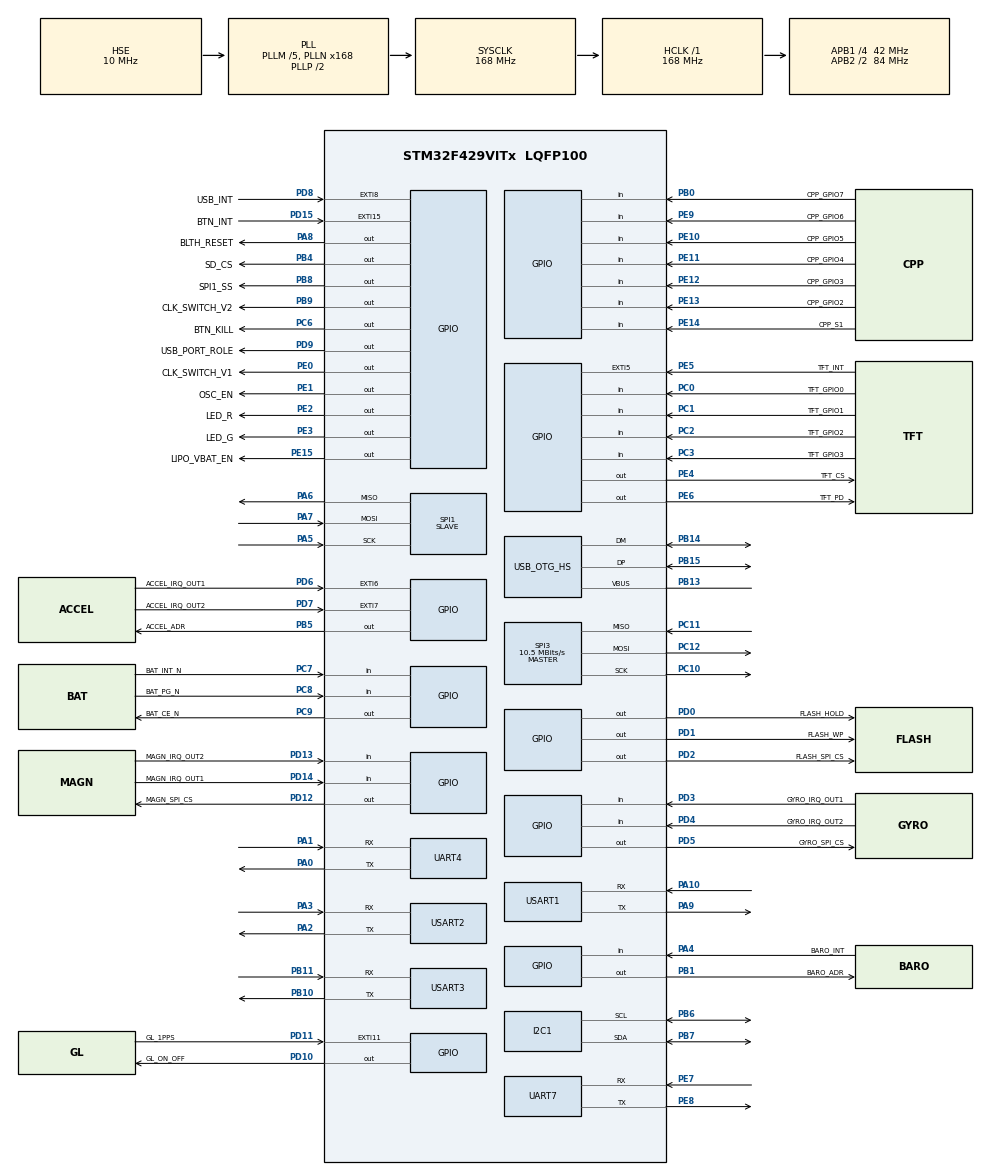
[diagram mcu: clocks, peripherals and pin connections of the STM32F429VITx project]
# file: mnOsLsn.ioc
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Dma.Request0=SPI3_TX
Dma.Request1=SPI3_RX
Dma.Request2=UART4_RX
Dma.Request3=USART2_RX
Dma.Request4=UART4_TX
Dma.Request5=USART2_TX
Dma.Request6=USART3_RX
Dma.Request7=UART7_RX
Dma.Request8=USART1_RX
Dma.SPI3_RX.1.Direction=DMA_PERIPH_TO_MEMORY
Dma.SPI3_RX.1.FIFOMode=DMA_FIFOMODE_DISABLE
Dma.SPI3_RX.1.Instance=DMA1_Stream0
Dma.SPI3_RX.1.MemDataAlignment=DMA_MDATAALIGN_BYTE
Dma.SPI3_RX.1.MemInc=DMA_MINC_ENABLE
Dma.SPI3_RX.1.Mode=DMA_NORMAL
Dma.SPI3_RX.1.PeriphDataAlignment=DMA_PDATAALIGN_BYTE
Dma.SPI3_RX.1.PeriphInc=DMA_PINC_DISABLE
Dma.SPI3_RX.1.Priority=DMA_PRIORITY_MEDIUM
Dma.SPI3_TX.0.Direction=DMA_MEMORY_TO_PERIPH
Dma.SPI3_TX.0.FIFOMode=DMA_FIFOMODE_DISABLE
Dma.SPI3_TX.0.Instance=DMA1_Stream7
Dma.SPI3_TX.0.MemDataAlignment=DMA_MDATAALIGN_BYTE
Dma.SPI3_TX.0.MemInc=DMA_MINC_ENABLE
Dma.SPI3_TX.0.Mode=DMA_NORMAL
Dma.SPI3_TX.0.PeriphDataAlignment=DMA_PDATAALIGN_BYTE
Dma.SPI3_TX.0.PeriphInc=DMA_PINC_DISABLE
Dma.SPI3_TX.0.Priority=DMA_PRIORITY_MEDIUM
Dma.UART4_RX.2.Direction=DMA_PERIPH_TO_MEMORY
Dma.UART4_RX.2.FIFOMode=DMA_FIFOMODE_DISABLE
Dma.UART4_RX.2.Instance=DMA1_Stream2
Dma.UART4_RX.2.MemDataAlignment=DMA_MDATAALIGN_BYTE
Dma.UART4_RX.2.MemInc=DMA_MINC_ENABLE
Dma.UART4_RX.2.Mode=DMA_CIRCULAR
Dma.UART4_RX.2.PeriphDataAlignment=DMA_PDATAALIGN_BYTE
Dma.UART4_RX.2.PeriphInc=DMA_PINC_DISABLE
Dma.UART4_RX.2.Priority=DMA_PRIORITY_HIGH
Dma.UART4_TX.4.Direction=DMA_MEMORY_TO_PERIPH
Dma.UART4_TX.4.FIFOMode=DMA_FIFOMODE_DISABLE
Dma.UART4_TX.4.Instance=DMA1_Stream4
Dma.UART4_TX.4.MemDataAlignment=DMA_MDATAALIGN_BYTE
Dma.UART4_TX.4.MemInc=DMA_MINC_ENABLE
Dma.UART4_TX.4.Mode=DMA_NORMAL
Dma.UART4_TX.4.PeriphDataAlignment=DMA_PDATAALIGN_BYTE
Dma.UART4_TX.4.PeriphInc=DMA_PINC_DISABLE
Dma.UART4_TX.4.Priority=DMA_PRIORITY_LOW
Dma.UART7_RX.7.Direction=DMA_PERIPH_TO_MEMORY
Dma.UART7_RX.7.FIFOMode=DMA_FIFOMODE_DISABLE
Dma.UART7_RX.7.Instance=DMA1_Stream3
Dma.UART7_RX.7.MemDataAlignment=DMA_MDATAALIGN_BYTE
Dma.UART7_RX.7.MemInc=DMA_MINC_ENABLE
Dma.UART7_RX.7.Mode=DMA_CIRCULAR
Dma.UART7_RX.7.PeriphDataAlignment=DMA_PDATAALIGN_BYTE
Dma.UART7_RX.7.PeriphInc=DMA_PINC_DISABLE
Dma.UART7_RX.7.Priority=DMA_PRIORITY_HIGH
Dma.USART1_RX.8.Direction=DMA_PERIPH_TO_MEMORY
Dma.USART1_RX.8.FIFOMode=DMA_FIFOMODE_DISABLE
Dma.USART1_RX.8.Instance=DMA2_Stream2
Dma.USART1_RX.8.MemDataAlignment=DMA_MDATAALIGN_BYTE
Dma.USART1_RX.8.MemInc=DMA_MINC_ENABLE
Dma.USART1_RX.8.Mode=DMA_CIRCULAR
Dma.USART1_RX.8.PeriphDataAlignment=DMA_PDATAALIGN_BYTE
Dma.USART1_RX.8.PeriphInc=DMA_PINC_DISABLE
Dma.USART1_RX.8.Priority=DMA_PRIORITY_MEDIUM
Dma.USART2_RX.3.Direction=DMA_PERIPH_TO_MEMORY
Dma.USART2_RX.3.FIFOMode=DMA_FIFOMODE_DISABLE
Dma.USART2_RX.3.Instance=DMA1_Stream5
Dma.USART2_RX.3.MemDataAlignment=DMA_MDATAALIGN_BYTE
Dma.USART2_RX.3.MemInc=DMA_MINC_ENABLE
Dma.USART2_RX.3.Mode=DMA_CIRCULAR
Dma.USART2_RX.3.PeriphDataAlignment=DMA_PDATAALIGN_BYTE
Dma.USART2_RX.3.PeriphInc=DMA_PINC_DISABLE
Dma.USART2_RX.3.Priority=DMA_PRIORITY_HIGH
Dma.USART2_TX.5.Direction=DMA_MEMORY_TO_PERIPH
Dma.USART2_TX.5.FIFOMode=DMA_FIFOMODE_DISABLE
Dma.USART2_TX.5.Instance=DMA1_Stream6
Dma.USART2_TX.5.MemDataAlignment=DMA_MDATAALIGN_BYTE
Dma.USART2_TX.5.MemInc=DMA_MINC_ENABLE
Dma.USART2_TX.5.Mode=DMA_NORMAL
Dma.USART2_TX.5.PeriphDataAlignment=DMA_PDATAALIGN_BYTE
Dma.USART2_TX.5.PeriphInc=DMA_PINC_DISABLE
Dma.USART2_TX.5.Priority=DMA_PRIORITY_LOW
Dma.USART3_RX.6.Direction=DMA_PERIPH_TO_MEMORY
Dma.USART3_RX.6.FIFOMode=DMA_FIFOMODE_DISABLE
Dma.USART3_RX.6.Instance=DMA1_Stream1
Dma.USART3_RX.6.MemDataAlignment=DMA_MDATAALIGN_BYTE
Dma.USART3_RX.6.MemInc=DMA_MINC_ENABLE
Dma.USART3_RX.6.Mode=DMA_CIRCULAR
Dma.USART3_RX.6.PeriphDataAlignment=DMA_PDATAALIGN_BYTE
Dma.USART3_RX.6.PeriphInc=DMA_PINC_DISABLE
Dma.USART3_RX.6.Priority=DMA_PRIORITY_HIGH
FATFS._FS_LOCK=3
FATFS._USE_LFN=3
FATFS._USE_MUTEX=1
FATFS._USE_STRFUNC=1
FREERTOS.BinarySemaphores01=semSpi,Dynamic,NULL;semInitPpm,Dynamic,NULL;semSyncTime,Dynamic,NULL
FREERTOS.Queues01=qSpi,16,SpiQNode,0,Dynamic,NULL,NULL;qI2c,16,I2cQNode,0,Dynamic,NULL,NULL;qGNSS_Tx1,16,String,0,Dynamic,NULL,NULL;qPPM_Tx0,16,String,0,Dynamic,NULL,NULL;qCDC_Rx,16,CDCRxData,0,Dynamic,NULL,NULL;qCDC_Tx,16,String,0,Dynamic,NULL,NULL;qMI_Tx,16,String,0,Dynamic,NULL,NULL;qJetTx,16,String,0,Dynamic,NULL,NULL;qBlthTx,16,String,0,Dynamic,NULL,NULL
FREERTOS.Tasks01=main,24,224,start_main,Default,NULL,Dynamic,NULL,NULL
FREERTOS.Timers01=tmrSyncTime,callbackTmrSyncTime,osTimerPeriodic,Default,NULL,Dynamic,NULL
FREERTOS.configCHECK_FOR_STACK_OVERFLOW=2
FREERTOS.configGENERATE_RUN_TIME_STATS=1
FREERTOS.configTOTAL_HEAP_SIZE=131072
FREERTOS.configUSE_MALLOC_FAILED_HOOK=1
FREERTOS.configUSE_NEWLIB_REENTRANT=1
FREERTOS.configUSE_POSIX_ERRNO=0
FREERTOS.configUSE_STATS_FORMATTING_FUNCTIONS=1
I2C1.AddressingMode=I2C_ADDRESSINGMODE_7BIT
I2C1.DualAddressMode=I2C_DUALADDRESS_DISABLE
I2C1.GeneralCallMode=I2C_GENERALCALL_DISABLE
I2C1.I2C_Mode=I2C_Fast
I2C1.NoStretchMode=I2C_NOSTRETCH_DISABLE
I2C1.OwnAddress=0
Mcu.Family=STM32F4
Mcu.Name=STM32F429VITx
Mcu.Package=LQFP100
NVIC.DMA1_Stream0_IRQn=true\:5\:0\:false\:false\:true\:true\:false\:true\:true
NVIC.DMA1_Stream1_IRQn=true\:5\:0\:false\:false\:true\:true\:false\:true\:true
NVIC.DMA1_Stream2_IRQn=true\:5\:0\:false\:false\:true\:true\:false\:true\:true
NVIC.DMA1_Stream3_IRQn=true\:5\:0\:false\:false\:true\:true\:false\:true\:true
NVIC.DMA1_Stream4_IRQn=true\:5\:0\:false\:false\:true\:true\:false\:true\:true
NVIC.DMA1_Stream5_IRQn=true\:5\:0\:false\:false\:true\:true\:false\:true\:true
NVIC.DMA1_Stream6_IRQn=true\:5\:0\:false\:false\:true\:true\:false\:true\:true
NVIC.DMA1_Stream7_IRQn=true\:5\:0\:false\:false\:true\:true\:false\:true\:true
NVIC.DMA2_Stream2_IRQn=true\:5\:0\:false\:false\:true\:true\:false\:true\:true
NVIC.EXTI15_10_IRQn=true\:5\:0\:false\:false\:true\:true\:true\:true\:true
NVIC.OTG_HS_IRQn=true\:5\:0\:false\:false\:true\:true\:false\:true\:true
NVIC.PriorityGroup=NVIC_PRIORITYGROUP_4
NVIC.TIM1_UP_TIM10_IRQn=true\:0\:0\:false\:false\:true\:false\:false\:true\:true
NVIC.TimeBase=TIM1_UP_TIM10_IRQn
NVIC.TimeBaseIP=TIM1
PA0/WKUP.Mode=Asynchronous
PA0/WKUP.Signal=UART4_TX
PA1.Mode=Asynchronous
PA1.Signal=UART4_RX
PA10.Mode=Asynchronous
PA10.Signal=USART1_RX
PA11.Signal=USART1_CTS
PA12.Signal=USART1_RTS
PA13.Mode=Serial_Wire
PA13.Signal=SYS_JTMS-SWDIO
PA14.Mode=Serial_Wire
PA14.Signal=SYS_JTCK-SWCLK
PA2.Mode=Asynchronous
PA2.Signal=USART2_TX
PA3.Mode=Asynchronous
PA3.Signal=USART2_RX
PA4.GPIO_Label=BARO_INT
PA4.Signal=GPIO_Input
PA5.Mode=Full_Duplex_Slave
PA5.Signal=SPI1_SCK
PA6.Mode=Full_Duplex_Slave
PA6.Signal=SPI1_MISO
PA7.Mode=Full_Duplex_Slave
PA7.Signal=SPI1_MOSI
PA8.GPIO_Label=BLTH_RESET
PA8.GPIO_Speed=GPIO_SPEED_FREQ_VERY_HIGH
PA8.Signal=GPIO_Output
PA9.Mode=Asynchronous
PA9.Signal=USART1_TX
PB0.GPIO_Label=CPP_GPIO7
PB0.Signal=GPIO_Input
PB1.GPIO_Label=BARO_ADR
PB1.GPIO_Speed=GPIO_SPEED_FREQ_LOW
PB1.Signal=GPIO_Output
PB10.Mode=Asynchronous
PB10.Signal=USART3_TX
PB11.Mode=Asynchronous
PB11.Signal=USART3_RX
PB12.Signal=USB_OTG_HS_ID
PB13.Mode=Activate_VBUS_FS
PB13.Signal=USB_OTG_HS_VBUS
PB14.Mode=Device_Only_FS
PB14.Signal=USB_OTG_HS_DM
PB15.Mode=Device_Only_FS
PB15.Signal=USB_OTG_HS_DP
PB4.GPIO_Label=SD_CS
PB4.GPIO_Speed=GPIO_SPEED_FREQ_VERY_HIGH
PB4.PinState=GPIO_PIN_SET
PB4.Signal=GPIO_Output
PB5.GPIO_Label=ACCEL_ADR
PB5.Signal=GPIO_Output
PB6.GPIO_Pu=GPIO_PULLUP
PB6.Mode=I2C
PB6.Signal=I2C1_SCL
PB7.GPIO_Pu=GPIO_PULLUP
PB7.Mode=I2C
PB7.Signal=I2C1_SDA
PB8.GPIO_Label=SPI1_SS
PB8.GPIO_Speed=GPIO_SPEED_FREQ_VERY_HIGH
PB8.PinState=GPIO_PIN_SET
PB8.Signal=GPIO_Output
PB9.GPIO_Label=CLK_SWITCH_V2
PB9.GPIO_Speed=GPIO_SPEED_FREQ_VERY_HIGH
PB9.Signal=GPIO_Output
PC0.GPIO_Label=TFT_GPIO0
PC0.Signal=GPIO_Input
PC1.GPIO_Label=TFT_GPIO1
PC1.Signal=GPIO_Input
PC10.Mode=Full_Duplex_Master
PC10.Signal=SPI3_SCK
PC11.Mode=Full_Duplex_Master
PC11.Signal=SPI3_MISO
PC12.Mode=Full_Duplex_Master
PC12.Signal=SPI3_MOSI
PC2.GPIO_Label=TFT_GPIO2
PC2.Signal=GPIO_Input
PC3.GPIO_Label=TFT_GPIO3
PC3.Signal=GPIO_Input
PC6.GPIO_Label=BTN_KILL
PC6.GPIO_Speed=GPIO_SPEED_FREQ_VERY_HIGH
PC6.PinState=GPIO_PIN_SET
PC6.Signal=GPIO_Output
PC7.GPIO_Label=BAT_INT_N
PC7.Signal=GPIO_Input
PC8.GPIO_Label=BAT_PG_N
PC8.Signal=GPIO_Input
PC9.GPIO_Label=BAT_CE_N
PC9.GPIO_Speed=GPIO_SPEED_FREQ_VERY_HIGH
PC9.PinState=GPIO_PIN_RESET
PC9.Signal=GPIO_Output
PD0.GPIO_Label=FLASH_HOLD
PD0.GPIO_Speed=GPIO_SPEED_FREQ_VERY_HIGH
PD0.Signal=GPIO_Output
PD1.GPIO_Label=FLASH_WP
PD1.GPIO_Speed=GPIO_SPEED_FREQ_VERY_HIGH
PD1.Signal=GPIO_Output
PD10.GPIO_Label=GL_ON_OFF
PD10.GPIO_Speed=GPIO_SPEED_FREQ_VERY_HIGH
PD10.Signal=GPIO_Output
PD11.GPIO_Label=GL_1PPS
PD11.Signal=GPXTI11
PD12.GPIO_Label=MAGN_SPI_CS
PD12.GPIO_Speed=GPIO_SPEED_FREQ_VERY_HIGH
PD12.PinState=GPIO_PIN_SET
PD12.Signal=GPIO_Output
PD13.GPIO_Label=MAGN_IRQ_OUT2
PD13.Signal=GPIO_Input
PD14.GPIO_Label=MAGN_IRQ_OUT1
PD14.Signal=GPIO_Input
PD15.GPIO_Label=BTN_INT
PD15.GPIO_ModeDefaultEXTI=GPIO_MODE_IT_FALLING
PD15.Signal=GPXTI15
PD2.GPIO_Label=FLASH_SPI_CS
PD2.GPIO_Speed=GPIO_SPEED_FREQ_VERY_HIGH
PD2.PinState=GPIO_PIN_SET
PD2.Signal=GPIO_Output
PD3.GPIO_Label=GYRO_IRQ_OUT1
PD3.Signal=GPIO_Input
PD4.GPIO_Label=GYRO_IRQ_OUT2
PD4.Signal=GPIO_Input
PD5.GPIO_Label=GYRO_SPI_CS
PD5.GPIO_Speed=GPIO_SPEED_FREQ_VERY_HIGH
PD5.PinState=GPIO_PIN_SET
PD5.Signal=GPIO_Output
PD6.GPIO_Label=ACCEL_IRQ_OUT1
PD6.GPIO_ModeDefaultEXTI=GPIO_MODE_IT_FALLING
PD6.Signal=GPXTI6
PD7.GPIO_Label=ACCEL_IRQ_OUT2
PD7.GPIO_ModeDefaultEXTI=GPIO_MODE_IT_FALLING
PD7.Signal=GPXTI7
PD8.GPIO_Label=USB_INT
PD8.GPIO_ModeDefaultEXTI=GPIO_MODE_IT_FALLING
PD8.GPIO_PuPd=GPIO_PULLUP
PD8.Signal=GPXTI8
PD9.GPIO_Label=USB_PORT_ROLE
PD9.GPIO_Speed=GPIO_SPEED_FREQ_VERY_HIGH
PD9.Signal=GPIO_Output
PE0.GPIO_Label=CLK_SWITCH_V1
PE0.GPIO_Speed=GPIO_SPEED_FREQ_VERY_HIGH
PE0.Signal=GPIO_Output
PE1.GPIO_Label=OSC_EN
PE1.GPIO_Speed=GPIO_SPEED_FREQ_VERY_HIGH
PE1.Signal=GPIO_Output
PE10.GPIO_Label=CPP_GPIO5
PE10.Signal=GPIO_Input
PE11.GPIO_Label=CPP_GPIO4
PE11.Signal=GPIO_Input
PE12.GPIO_Label=CPP_GPIO3
PE12.Signal=GPIO_Input
PE13.GPIO_Label=CPP_GPIO2
PE13.Signal=GPIO_Input
PE14.GPIO_Label=CPP_S1
PE14.Signal=GPIO_Input
PE15.GPIO_Label=LIPO_VBAT_EN
PE15.GPIO_Speed=GPIO_SPEED_FREQ_VERY_HIGH
PE15.Signal=GPIO_Output
PE2.GPIO_Label=LED_R
PE2.Signal=GPIO_Output
PE3.GPIO_Label=LED_G
PE3.Signal=GPIO_Output
PE4.GPIO_Label=TFT_CS
PE4.GPIO_Speed=GPIO_SPEED_FREQ_VERY_HIGH
PE4.PinState=GPIO_PIN_SET
PE4.Signal=GPIO_Output
PE5.GPIO_Label=TFT_INT
PE5.GPIO_ModeDefaultEXTI=GPIO_MODE_IT_FALLING
PE5.Signal=GPXTI5
PE6.GPIO_Label=TFT_PD
PE6.GPIO_Speed=GPIO_SPEED_FREQ_VERY_HIGH
PE6.PinState=GPIO_PIN_RESET
PE6.Signal=GPIO_Output
PE7.Mode=Asynchronous
PE7.Signal=UART7_RX
PE8.Mode=Asynchronous
PE8.Signal=UART7_TX
PE9.GPIO_Label=CPP_GPIO6
PE9.Signal=GPIO_Input
PH0/OSC_IN.Mode=HSE-External-Clock-Source
PH0/OSC_IN.Signal=RCC_OSC_IN
PH1/OSC_OUT.Mode=HSE-External-Clock-Source
PH1/OSC_OUT.Signal=RCC_OSC_OUT
ProjectManager.HeapSize=0x200
ProjectManager.StackSize=0x400
ProjectManager.TargetToolchain=STM32CubeIDE
RCC.48MHZClocksFreq_Value=48000000
RCC.AHBFreq_Value=168000000
RCC.APB1CLKDivider=RCC_HCLK_DIV4
RCC.APB1Freq_Value=42000000
RCC.APB1TimFreq_Value=84000000
RCC.APB2CLKDivider=RCC_HCLK_DIV2
RCC.APB2Freq_Value=84000000
RCC.APB2TimFreq_Value=168000000
RCC.CortexFreq_Value=168000000
RCC.HCLKFreq_Value=168000000
RCC.HSE_VALUE=10000000
RCC.HSI_VALUE=16000000
RCC.LSE_VALUE=32768
RCC.PLLM=5
RCC.PLLN=168
RCC.PLLQ=7
RCC.SYSCLKFreq_VALUE=168000000
RCC.SYSCLKSource=RCC_SYSCLKSOURCE_PLLCLK
RCC.VCOOutputFreq_Value=336000000
RTC.Format=RTC_FORMAT_BIN
RTC.SynchPrediv=249
RTC.WeekDay=RTC_WEEKDAY_FRIDAY
RTC.Year=41
SPI1.Direction=SPI_DIRECTION_2LINES
SPI1.Mode=SPI_MODE_SLAVE
SPI1.VirtualType=VM_SLAVE
SPI3.BaudRatePrescaler=SPI_BAUDRATEPRESCALER_4
SPI3.CalculateBaudRate=10.5 MBits/s
SPI3.Direction=SPI_DIRECTION_2LINES
SPI3.Mode=SPI_MODE_MASTER
SPI3.VirtualType=VM_MASTER
UART4.VirtualMode=Asynchronous
UART7.VirtualMode=Asynchronous
USART1.VirtualMode=VM_ASYNC
USART2.VirtualMode=VM_ASYNC
USART3.VirtualMode=VM_ASYNC
USB_DEVICE.CLASS_NAME_HS=CDC
USB_DEVICE.VirtualMode-CDC_HS=Cdc
USB_DEVICE.VirtualModeHS=Cdc_HS
USB_OTG_HS.VirtualMode-Device_Only_FS=Device_Only_FS
USB_OTG_HS.dma_enable-Device_Only_FS=ENABLE
VP_FATFS_VS_Generic.Mode=User_defined
VP_FREERTOS_VS_CMSIS_V2.Mode=CMSIS_V2
VP_RTC_VS_RTC_Activate.Mode=RTC_Enabled
VP_RTC_VS_RTC_Calendar.Mode=RTC_Calendar
VP_SYS_VS_tim1.Mode=TIM1
VP_USB_DEVICE_VS_USB_DEVICE_CDC_HS.Mode=CDC_HS
board=custom

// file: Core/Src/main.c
/* USER CODE BEGIN Header */
/**
  ******************************************************************************
  * @file           : main.c
  * @brief          : Main program body
  ******************************************************************************
  * @attention
  *
  * <h2><center>&copy; Copyright (c) 2021 STMicroelectronics.
  * All rights reserved.</center></h2>
  *
  * This software component is licensed by ST under BSD 3-Clause license,
  * the "License"; You may not use this file except in compliance with the
  * License. You may obtain a copy of the License at:
  *                        opensource.org/licenses/BSD-3-Clause
  *
  ******************************************************************************
  */
/* USER CODE END Header */
#include "main.h"
#include "cmsis_os.h"
#include "dma.h"
#include "fatfs.h"
#include "i2c.h"
#include "rtc.h"
#include "spi.h"
#include "usart.h"
#include "usb_device.h"
#include "gpio.h"

/* USER CODE BEGIN Includes */
#include "clk_osc.h"
#include "clk_key.h"
#include "system_clk.h"
/* USER CODE END Includes */

void SystemClock_Config(void);
void MX_FREERTOS_Init(void);
/* USER CODE BEGIN PFP */
void SystemClock_ConfigHSI(void);
/* USER CODE END PFP */

int main(void)
{

  /* MCU Configuration--------------------------------------------------------*/

  /* Reset of all peripherals, Initializes the Flash interface and the Systick. */
  HAL_Init();

  /* USER CODE BEGIN Init */
  goto skipSystemClkConfig;
  /* USER CODE END Init */

  /* Configure the system clock */
  SystemClock_Config();

  /* USER CODE BEGIN SysInit */
skipSystemClkConfig:
  SystemClock_ConfigHSI();
  /* USER CODE END SysInit */

  /* Initialize all configured peripherals */
  MX_GPIO_Init();
  MX_DMA_Init();
  MX_I2C1_Init();
  MX_SPI3_Init();
  MX_UART4_Init();
  MX_USART1_UART_Init();
  MX_USART2_UART_Init();
  MX_UART7_Init();
  MX_USART3_UART_Init();
  MX_FATFS_Init();
  MX_RTC_Init();
  MX_SPI1_Init();
  /* USER CODE BEGIN 2 */
  i2c_init();
  clk_osc_config_bp();
  clk_osc_en(oscEnable);
  clk_key_sel_src(clkInternal);
  if (clk_sel_pll_hse()) {
    Error_Handler();
  }
  /* USER CODE END 2 */

  /* Init scheduler */
  osKernelInitialize();  /* Call init function for freertos objects (in freertos.c) */
  MX_FREERTOS_Init();

  /* Start scheduler */
  osKernelStart();

  /* We should never get here as control is now taken by the scheduler */
  /* Infinite loop */
  while (1)
  {

  }
}

void SystemClock_Config(void)
{
  RCC_OscInitTypeDef RCC_OscInitStruct = {0};
  RCC_ClkInitTypeDef RCC_ClkInitStruct = {0};

  /** Configure the main internal regulator output voltage
  */
  __HAL_RCC_PWR_CLK_ENABLE();
  __HAL_PWR_VOLTAGESCALING_CONFIG(PWR_REGULATOR_VOLTAGE_SCALE1);

  /** Initializes the RCC Oscillators according to the specified parameters
  * in the RCC_OscInitTypeDef structure.
  */
  RCC_OscInitStruct.OscillatorType = RCC_OSCILLATORTYPE_LSI|RCC_OSCILLATORTYPE_HSE;
  RCC_OscInitStruct.HSEState = RCC_HSE_BYPASS;
  RCC_OscInitStruct.LSIState = RCC_LSI_ON;
  RCC_OscInitStruct.PLL.PLLState = RCC_PLL_ON;
  RCC_OscInitStruct.PLL.PLLSource = RCC_PLLSOURCE_HSE;
  RCC_OscInitStruct.PLL.PLLM = 5;
  RCC_OscInitStruct.PLL.PLLN = 168;
  RCC_OscInitStruct.PLL.PLLP = RCC_PLLP_DIV2;
  RCC_OscInitStruct.PLL.PLLQ = 7;
  if (HAL_RCC_OscConfig(&RCC_OscInitStruct) != HAL_OK)
  {
    Error_Handler();
  }

  /** Initializes the CPU, AHB and APB buses clocks
  */
  RCC_ClkInitStruct.ClockType = RCC_CLOCKTYPE_HCLK|RCC_CLOCKTYPE_SYSCLK
                              |RCC_CLOCKTYPE_PCLK1|RCC_CLOCKTYPE_PCLK2;
  RCC_ClkInitStruct.SYSCLKSource = RCC_SYSCLKSOURCE_PLLCLK;
  RCC_ClkInitStruct.AHBCLKDivider = RCC_SYSCLK_DIV1;
  RCC_ClkInitStruct.APB1CLKDivider = RCC_HCLK_DIV4;
  RCC_ClkInitStruct.APB2CLKDivider = RCC_HCLK_DIV2;

  if (HAL_RCC_ClockConfig(&RCC_ClkInitStruct, FLASH_LATENCY_5) != HAL_OK)
  {
    Error_Handler();
  }
}

/* USER CODE BEGIN 4 */
void SystemClock_ConfigHSI(void)
{
  RCC_OscInitTypeDef RCC_OscInitStruct = {0};
  RCC_ClkInitTypeDef RCC_ClkInitStruct = {0};
  RCC_PeriphCLKInitTypeDef PeriphClkInitStruct = {0};

  /** Configure the main internal regulator output voltage
  */
  __HAL_RCC_PWR_CLK_ENABLE();
  __HAL_PWR_VOLTAGESCALING_CONFIG(PWR_REGULATOR_VOLTAGE_SCALE1);
  /** Initializes the RCC Oscillators according to the specified parameters
  * in the RCC_OscInitTypeDef structure.
  */
  RCC_OscInitStruct.OscillatorType = RCC_OSCILLATORTYPE_HSI|RCC_OSCILLATORTYPE_LSI;
  RCC_OscInitStruct.HSIState = RCC_HSI_ON;
  RCC_OscInitStruct.HSICalibrationValue = RCC_HSICALIBRATION_DEFAULT;
  RCC_OscInitStruct.LSIState = RCC_LSI_ON;
  RCC_OscInitStruct.PLL.PLLState = RCC_PLL_ON;
  RCC_OscInitStruct.PLL.PLLSource = RCC_PLLSOURCE_HSI;
  RCC_OscInitStruct.PLL.PLLM = 8;
  RCC_OscInitStruct.PLL.PLLN = 168;
  RCC_OscInitStruct.PLL.PLLP = RCC_PLLP_DIV2;
  RCC_OscInitStruct.PLL.PLLQ = 7;
  if (HAL_RCC_OscConfig(&RCC_OscInitStruct) != HAL_OK)
  {
    Error_Handler();
  }
  /** Initializes the CPU, AHB and APB buses clocks
  */
  RCC_ClkInitStruct.ClockType = RCC_CLOCKTYPE_HCLK|RCC_CLOCKTYPE_SYSCLK
                              |RCC_CLOCKTYPE_PCLK1|RCC_CLOCKTYPE_PCLK2;
  RCC_ClkInitStruct.SYSCLKSource = RCC_SYSCLKSOURCE_PLLCLK;
  RCC_ClkInitStruct.AHBCLKDivider = RCC_SYSCLK_DIV1;
  RCC_ClkInitStruct.APB1CLKDivider = RCC_HCLK_DIV4;
  RCC_ClkInitStruct.APB2CLKDivider = RCC_HCLK_DIV2;

  if (HAL_RCC_ClockConfig(&RCC_ClkInitStruct, FLASH_LATENCY_5) != HAL_OK)
  {
    Error_Handler();
  }
  PeriphClkInitStruct.PeriphClockSelection = RCC_PERIPHCLK_RTC;
  PeriphClkInitStruct.RTCClockSelection = RCC_RTCCLKSOURCE_LSI;
  if (HAL_RCCEx_PeriphCLKConfig(&PeriphClkInitStruct) != HAL_OK)
  {
    Error_Handler();
  }
}
/* USER CODE END 4 */

void HAL_TIM_PeriodElapsedCallback(TIM_HandleTypeDef *htim)
{
  if (htim->Instance == TIM1) {
    HAL_IncTick();
  }
}

void Error_Handler(void)
{
  __disable_irq();
  while (1)
  {
  }
}

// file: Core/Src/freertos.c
/* USER CODE BEGIN Header */
/**
  ******************************************************************************
  * File Name          : freertos.c
  * Description        : Code for freertos applications
  ******************************************************************************
  * @attention
  *
  * <h2><center>&copy; Copyright (c) 2021 STMicroelectronics.
  * All rights reserved.</center></h2>
  *
  * This software component is licensed by ST under Ultimate Liberty license
  * SLA0044, the "License"; You may not use this file except in compliance with
  * the License. You may obtain a copy of the License at:
  *                             www.st.com/SLA0044
  *
  ******************************************************************************
  */
/* USER CODE END Header */

#include "FreeRTOS.h"
#include "task.h"
#include "main.h"
#include "cmsis_os.h"

/* USER CODE BEGIN Includes */
#include <stdio.h>
#include <string.h>
#include "queue.h"
#include "semphr.h"
#include "timers.h"
#include "spi.h"
#include "usart.h"
#include "i2c.h"
#include "rtc.h"
#include "usbd_cdc_if.h"
#include "user_diskio_spi.h"
#include "fatfs.h"
#include "util_heap.h"
#include "util_string.h"
#include "led.h"
#include "bat_ctrl.h"
#include "usb_port_ctrl.h"
#include "sd_card.h"
#include "flow_ctrl.h"
#include "station.h"
#include "flash.h"
#include "ppm.h"
#include "jet.h"
#include "gnss.h"
#include "mi.h"
#include "rtc_if.h"
#include "a_lis331xx.h"
#include "g_l3gxx.h"
#include "m_lis3mdl.h"
#include "m_hmc5883l.h"
#include "b_bmp280.h"
#include "mt25q.h"
#include "ft_core.h"
#include "shutdown.h"
#include "app_ui_manager.h"
#include "bluetooth.h"
/* USER CODE END Includes */

/* USER CODE BEGIN Variables */
ShutdownState shutDownFl = shdownNone;
static Bluetooth *bluetooth = NULL;
/* USER CODE END Variables */
/* Definitions for main */
osThreadId_t mainHandle;
const osThreadAttr_t main_attributes = {
  .name = "main",
  .stack_size = 224 * 4,
  .priority = (osPriority_t) osPriorityNormal,
};
/* Definitions for qSpi */
osMessageQueueId_t qSpiHandle;
const osMessageQueueAttr_t qSpi_attributes = {
  .name = "qSpi"
};
/* Definitions for qI2c */
osMessageQueueId_t qI2cHandle;
const osMessageQueueAttr_t qI2c_attributes = {
  .name = "qI2c"
};
/* Definitions for qGNSS_Tx1 */
osMessageQueueId_t qGNSS_Tx1Handle;
const osMessageQueueAttr_t qGNSS_Tx1_attributes = {
  .name = "qGNSS_Tx1"
};
/* Definitions for qPPM_Tx0 */
osMessageQueueId_t qPPM_Tx0Handle;
const osMessageQueueAttr_t qPPM_Tx0_attributes = {
  .name = "qPPM_Tx0"
};
/* Definitions for qCDC_Rx */
osMessageQueueId_t qCDC_RxHandle;
const osMessageQueueAttr_t qCDC_Rx_attributes = {
  .name = "qCDC_Rx"
};
/* Definitions for qCDC_Tx */
osMessageQueueId_t qCDC_TxHandle;
const osMessageQueueAttr_t qCDC_Tx_attributes = {
  .name = "qCDC_Tx"
};
/* Definitions for qMI_Tx */
osMessageQueueId_t qMI_TxHandle;
const osMessageQueueAttr_t qMI_Tx_attributes = {
  .name = "qMI_Tx"
};
/* Definitions for qJetTx */
osMessageQueueId_t qJetTxHandle;
const osMessageQueueAttr_t qJetTx_attributes = {
  .name = "qJetTx"
};
/* Definitions for qBlthTx */
osMessageQueueId_t qBlthTxHandle;
const osMessageQueueAttr_t qBlthTx_attributes = {
  .name = "qBlthTx"
};
/* Definitions for tmrSyncTime */
osTimerId_t tmrSyncTimeHandle;
const osTimerAttr_t tmrSyncTime_attributes = {
  .name = "tmrSyncTime"
};
/* Definitions for semSpi */
osSemaphoreId_t semSpiHandle;
const osSemaphoreAttr_t semSpi_attributes = {
  .name = "semSpi"
};
/* Definitions for semInitPpm */
osSemaphoreId_t semInitPpmHandle;
const osSemaphoreAttr_t semInitPpm_attributes = {
  .name = "semInitPpm"
};
/* Definitions for semSyncTime */
osSemaphoreId_t semSyncTimeHandle;
const osSemaphoreAttr_t semSyncTime_attributes = {
  .name = "semSyncTime"
};

/* USER CODE BEGIN FunctionPrototypes */
static void system_config();
Bluetooth* blth_instaince();
/* USER CODE END FunctionPrototypes */

void start_main(void *argument);
void callbackTmrSyncTime(void *argument);

extern void MX_USB_DEVICE_Init(void);
void MX_FREERTOS_Init(void); /* (MISRA C 2004 rule 8.1) */

/* Hook prototypes */
void configureTimerForRunTimeStats(void);
unsigned long getRunTimeCounterValue(void);
void vApplicationStackOverflowHook(xTaskHandle xTask, signed char *pcTaskName);
void vApplicationMallocFailedHook(void);

/* USER CODE BEGIN 1 */
/* Functions needed when configGENERATE_RUN_TIME_STATS is on */
__weak void configureTimerForRunTimeStats(void)
{
}

__weak unsigned long getRunTimeCounterValue(void)
{
  return xTaskGetTickCount();
}

Bluetooth* blth_instanse()
{
  return bluetooth;
}
/* USER CODE END 1 */

/* USER CODE BEGIN 4 */
void vApplicationStackOverflowHook(xTaskHandle xTask, signed char *pcTaskName)
{
   /* Run time stack overflow checking is performed if
   configCHECK_FOR_STACK_OVERFLOW is defined to 1 or 2. This hook function is
   called if a stack overflow is detected. */
}
/* USER CODE END 4 */

/* USER CODE BEGIN 5 */
void vApplicationMallocFailedHook(void)
{
   /* vApplicationMallocFailedHook() will only be called if
   configUSE_MALLOC_FAILED_HOOK is set to 1 in FreeRTOSConfig.h. It is a hook
   function that will get called if a call to pvPortMalloc() fails.
   pvPortMalloc() is called internally by the kernel whenever a task, queue,
   timer or semaphore is created. It is also called by various parts of the
   demo application. If heap_1.c or heap_2.c are used, then the size of the
   heap available to pvPortMalloc() is defined by configTOTAL_HEAP_SIZE in
   FreeRTOSConfig.h, and the xPortGetFreeHeapSize() API function can be used
   to query the size of free heap space that remains (although it does not
   provide information on how the remaining heap might be fragmented). */
}
/* USER CODE END 5 */

void MX_FREERTOS_Init(void) {

  /* Create the semaphores(s) */
  /* creation of semSpi */
  semSpiHandle = osSemaphoreNew(1, 1, &semSpi_attributes);

  /* creation of semInitPpm */
  semInitPpmHandle = osSemaphoreNew(1, 1, &semInitPpm_attributes);

  /* creation of semSyncTime */
  semSyncTimeHandle = osSemaphoreNew(1, 1, &semSyncTime_attributes);

  /* Create the timer(s) */
  /* creation of tmrSyncTime */
  tmrSyncTimeHandle = osTimerNew(callbackTmrSyncTime, osTimerPeriodic, NULL, &tmrSyncTime_attributes);

  /* Create the queue(s) */
  /* creation of qSpi */
  qSpiHandle = osMessageQueueNew (16, sizeof(SpiQNode), &qSpi_attributes);

  /* creation of qI2c */
  qI2cHandle = osMessageQueueNew (16, sizeof(I2cQNode), &qI2c_attributes);

  /* creation of qGNSS_Tx1 */
  qGNSS_Tx1Handle = osMessageQueueNew (16, sizeof(String), &qGNSS_Tx1_attributes);

  /* creation of qPPM_Tx0 */
  qPPM_Tx0Handle = osMessageQueueNew (16, sizeof(String), &qPPM_Tx0_attributes);

  /* creation of qCDC_Rx */
  qCDC_RxHandle = osMessageQueueNew (16, sizeof(CDCRxData), &qCDC_Rx_attributes);

  /* creation of qCDC_Tx */
  qCDC_TxHandle = osMessageQueueNew (16, sizeof(String), &qCDC_Tx_attributes);

  /* creation of qMI_Tx */
  qMI_TxHandle = osMessageQueueNew (16, sizeof(String), &qMI_Tx_attributes);

  /* creation of qJetTx */
  qJetTxHandle = osMessageQueueNew (16, sizeof(String), &qJetTx_attributes);

  /* creation of qBlthTx */
  qBlthTxHandle = osMessageQueueNew (16, sizeof(String), &qBlthTx_attributes);

  /* Create the thread(s) */
  /* creation of main */
  mainHandle = osThreadNew(start_main, NULL, &main_attributes);

}

void start_main(void *argument)
{
  /* init code for USB_DEVICE */
  MX_USB_DEVICE_Init();
  /* USER CODE BEGIN start_main */
  system_config();

  while(bTrue) {
    const uint32_t start = xTaskGetTickCount();

    osDelayUntil(start+pdMS_TO_TICKS(250));
  }
  /* USER CODE END start_main */
}

/* callbackTmrSyncTime function */
void callbackTmrSyncTime(void *argument)
{
  /* USER CODE BEGIN callbackTmrSyncTime */
  gnss_sync_time(&station);
  /* USER CODE END callbackTmrSyncTime */
}

/* USER CODE BEGIN Application */
static void start_service_interrupt(void *argument)
{
  while(bTrue) {
    const uint32_t start = xTaskGetTickCount();

    uint32_t intPending = EXTI->PR;
    if(intPending & USB_INT_Pin) {
      EXTI->PR = USB_INT_Pin;
      usbp_ctrl_clear_int();
    }
    if(intPending & TFT_INT_Pin) {
      EXTI->PR = TFT_INT_Pin;
//      uint8_t flags = ft_app_get_intfl(&dispHost);
    }
    if(intPending & BTN_INT_Pin) {
      EXTI->PR = BTN_INT_Pin;
      shutDownFl = shdownPend;
    }

    if(shutDownFl == shdownTrue)
      shutdown();

    osDelayUntil(start+pdMS_TO_TICKS(50));
  }
}

static void start_service_spi(void *argument)
{
  while(bTrue) {
    SpiQNode node;
    xQueueReceive(qSpiHandle, &node, portMAX_DELAY);

//    spi_cs(node.spi);
    if(node.spi == &spiIF_TFT) {
      spi_cs(node.spi);
      if(node.type == typeTxData) {
        spi_tx_dma(node.spi, node.data, node.dataSize);
        spi_wait_clear(node.spi);
        vPortFree(node.data);
      }
      else if(node.type == typeRxData) {
        spi_rx(node.spi, node.data, node.dataSize);
//        spi_rx_dma(node.spi, node.data, node.dataSize);
        spi_wait_clear(node.spi);
      }
      else if(node.type == typeTx) {
        uint8_t prefix[3];
        prefix[0] = 0x80 | (node.address >> 16 & 0x3F);
        prefix[1] = node.address >> 8;
        prefix[2] = node.address;
        spi_tx_dma(node.spi, prefix, sizeof(prefix));
        spi_wait_clear(node.spi);
        spi_tx_dma(node.spi, node.data, node.dataSize);
        spi_wait_clear(node.spi);
        vPortFree(node.data);
      }
      else {
        uint8_t prefix[4];
        prefix[0] = node.address >> 16 & 0x3F;
        prefix[1] = node.address >> 8;
        prefix[2] = node.address;
        prefix[3] = 0x00;
        spi_tx_dma(node.spi, prefix, sizeof(prefix));
        spi_wait_clear(node.spi);
        spi_rx(node.spi, node.data, node.dataSize);
//        spi_rx_dma(node.spi, node.data, node.dataSize);
        spi_wait_clear(node.spi);
      }
    }
    else if(node.spi == &spiIF_L3GD20H || node.spi == &spiIF_LIS3MDL) {
      spi_cs(node.spi);
      if(node.type == typeTx) {
        uint8_t prefix = 0x40 | (node.address & 0x3F);
        spi_tx_dma(node.spi, &prefix, sizeof(prefix));
        spi_wait_clear(node.spi);
        spi_tx_dma(node.spi, node.data, node.dataSize);
        spi_wait_clear(node.spi);
        vPortFree(node.data);
      }
      else {
        uint8_t prefix = 0xC0 | (node.address & 0x3F);
        spi_tx_dma(node.spi, &prefix, sizeof(prefix));
        spi_wait_clear(node.spi);
        spi_rx(node.spi, node.data, node.dataSize);
//        spi_rx_dma(node.spi, node.data, node.dataSize);
        spi_wait_clear(node.spi);
      }
    }
    else if(node.spi == &spiIF_SD) {
      switch(node.sdParam->type) {
        case sdInit:
          node.sdParam->result = USER_SPI_initialize(node.sdParam->pdrv);
          break;
        case sdRead:
          node.sdParam->result = USER_SPI_read(node.sdParam->pdrv, node.sdParam->buff,
                                               node.sdParam->sector, node.sdParam->count);
          break;
        case sdWrite:
          node.sdParam->result = USER_SPI_write(node.sdParam->pdrv, node.sdParam->buff,
                                                node.sdParam->sector, node.sdParam->count);
          break;
        case sdIoctl:
          node.sdParam->result = USER_SPI_ioctl(node.sdParam->pdrv, node.sdParam->cmd,
                                                node.sdParam->buffCmd);
          break;
      }
    }
    else if(node.spi == &spiIF_MT25Q) {
      switch(node.type) {
        case typeTx:
          mt25q_spi_send(&spiIF_MT25Q, node.cmd, node.address, node.addressSize, node.data, node.dataSize);
          break;
        case typeRx:
          mt25q_spi_receive(&spiIF_MT25Q, node.cmd, node.address, node.addressSize, node.data, node.dataSize);
          break;
        default:
          ;
      }
    }

    spi_decs(node.spi);
    if(node.ready)
      xSemaphoreGive(node.ready);
  }
}

static void start_service_i2c(void *argument)
{
  while(bTrue) {
    I2cQNode node;
    xQueueReceive(qI2cHandle, &node, portMAX_DELAY);

    if(node.type == typeTx) {
      uint16_t sizeAll = sizeof(node.address) + node.dataSize;
      uint8_t* txData = pvPortMalloc(sizeAll);
      memcpy(txData, &node.address, sizeof(node.address));
      memcpy(&txData[sizeof(node.address)], node.data, node.dataSize);
      vPortFree(node.data);
      i2c_tx(node.i2c, txData, sizeAll);
      vPortFree(txData);
    }
    else if(node.type == typeRx){
      i2c_tx(node.i2c, &node.address, sizeof(node.address));
      i2c_rx(node.i2c, node.data, node.dataSize);
    }
    else /* typeIsReady */ {
      if(node.dataSize > 0) {
        node.data[0] = i2c_is_ready(node.i2c);
      }
    }

    if(node.ready)
      xSemaphoreGive(node.ready);
  }
}

static void start_service_sensors(void *argument)
{
  g_l3gd20h_init();
  g_l3g4250d_init();
  g_l3gxx_config(&l3gd20h);
  g_l3gxx_config(&l3g4250d);
  a_lis331hh_init();
  a_lis331dlh_init();
  a_lis331xx_config(&lis331hh);
  a_lis331xx_config(&lis331dlh);
  m_lis3mdl_init();
  m_hmc5883l_init();
  m_lis3mdl_config(&lis3mdl);
  m_hmc5883l_config(&hmc5883l);
  b_bmp230_init();
  b_bmp230_config(&bmp230);

  bat_config();
  bat_out_en();
  uint8_t batteryCount = 0;

  while(bTrue) {
    const uint32_t start = xTaskGetTickCount();

    a_lis331xx_refresh_xyz(&lis331hh);
    a_lis331xx_refresh_xyz(&lis331dlh);
    m_lis3mdl_refresh_xyz(&lis3mdl);
    m_lis3mdl_refresh_temp(&lis3mdl);
    m_hmc5883l_refresh(&hmc5883l);
    b_bmp230_refresh(&bmp230);
    g_l3gxx_refresh_xyz(&l3gd20h);
    g_l3gxx_refresh_xyz(&l3g4250d);
    g_l3gxx_refresh_temp(&l3gd20h);
    g_l3gxx_refresh_temp(&l3g4250d);

    ++batteryCount;
    if(batteryCount == 10) {
      batteryCount = 0;
      bat_refresh_chrg_stat();
      bat_refresh_ibus();
      bat_refresh_ichrg();
      bat_refresh_vbus();
      bat_refresh_vbat();
      bat_refresh_vsys();
      bat_refresh_ts();
      bat_refresh_tdie();
    }

    osDelayUntil(start+pdMS_TO_TICKS(10));
  }
}

static void start_service_sd(void *argument)
{
  SD_Card *sd = sd_instance();
  sd_config(sd, &spiIF_SD);

  while(bTrue) {
    const uint32_t start = xTaskGetTickCount();
    sd_write_loop(sd);
    osDelayUntil(start+pdMS_TO_TICKS(10));
  }
}

static void start_gnss_rx1(void *argument)
{
  while(bTrue) {
    flow_gnss1_process(&flowCtrl, &station);
    osDelay(pdMS_TO_TICKS(10));
  }
}
static void start_gnss_tx1(void *argument)
{
  while(bTrue) {
    String str;
    xQueueReceive(qGNSS_Tx1Handle, &str, portMAX_DELAY);
    gnss_uart1_tx(&flowCtrl, &str);
    str_clear(&str);
  }
}

static void start_ppm_rx0(void *argument)
{
  while(bTrue) {
    flow_ppm0_process(&flowCtrl, &station);
    osDelay(pdMS_TO_TICKS(10));
  }
}

static void start_ppm_tx0(void *argument)
{
  while(bTrue) {
    String str;
    xQueueReceive(qPPM_Tx0Handle, &str, portMAX_DELAY);
    ppm_uart0_tx(&flowCtrl, &str);
    str_clear(&str);
  }
}

static void start_ppm_init(void *argument)
{
  osDelay(pdMS_TO_TICKS(20000)); //< Ожидание инициализации платы ППМ
  ppm_config(&station, &flowCtrl);
  mi_config(&station, &flowCtrl);
  vTaskDelete(NULL);
}

static void start_cdc_rx(void *argument)
{
  while(bTrue) {
    flow_com_process(&flowCtrl, &station);
    osDelay(pdMS_TO_TICKS(20));
  }
}

static void start_cdc_tx(void *argument)
{
  while(bTrue) {
    String str;
    String storage = make_str_null();
    while(xQueueReceive(qCDC_TxHandle, &str, 0) == pdTRUE)
      str_append_str_own(&storage, &str);
    if(storage.len)
      CDC_Transmit_HS((uint8_t*)str_data(&storage), str_length(&storage));
    str_clear(&storage);
    osDelay(pdMS_TO_TICKS(5));
  }
}

static void start_mi_rx(void *argument)
{
  HAL_UART_Receive_DMA(flowCtrl.raw.mi.uart, (uint8_t*)flowCtrl.raw.mi.searchItem.beginBuffer, flowCtrl.raw.mi.searchItem.sizeBuffer);
  while(bTrue) {
    flow_mi_process(&flowCtrl, &station);
    osDelay(pdMS_TO_TICKS(20));
  }
}

static void start_mi_tx(void *argument)
{
  while(bTrue) {
    String str;
    xQueueReceive(qMI_TxHandle, &str, portMAX_DELAY);
    HAL_UART_Transmit(flowCtrl.raw.mi.uart, (uint8_t*)str_data(&str), str_length(&str), 1000);
    str_clear(&str);
  }
}

static void start_jet_rx(void *argument)
{
  jet_config(&station, &flowCtrl);
  while(bTrue) {
    flow_jet_process(&flowCtrl, &station);
    osDelay(pdMS_TO_TICKS(20));
  }
}

static void start_jet_tx(void *argument)
{
  while(bTrue) {
    String str;
    xQueueReceive(qJetTxHandle, &str, portMAX_DELAY);
    HAL_UART_Transmit(flowCtrl.raw.jet.uart, (uint8_t*)str_data(&str), str_length(&str), 1000);
    str_clear(&str);
  }
}

static void start_bluetooth_tx(void *argument)
{
  while(bTrue) {
    String str;
    xQueueReceive(qBlthTxHandle, &str, portMAX_DELAY);
    blth_send(bluetooth, (uint8_t*)str.data, str.len);
    str_clear(&str);
  }
}

static void start_sta_regular(void *argument)
{
  while(bTrue) {
    const uint32_t start = xTaskGetTickCount();

    sta_send_telemetry(&station);
    sta_send_sys_info(&station);
    sta_send_sensor(&station);
    sta_calculate(&station);
    sta_send_jet(&flowCtrl, &station);

    flow_gnss0_tx_data(&flowCtrl, &station);
    flow_gnss1_tx_data(&flowCtrl, &station);

    osDelayUntil(start+pdMS_TO_TICKS(station.send.period));
  }
}

static void start_sync_time(void *argument)
{
  xSemaphoreTake(semSyncTimeHandle, portMAX_DELAY);
  while(bTrue) {
    xSemaphoreTake(semSyncTimeHandle, portMAX_DELAY);
    HAL_NVIC_DisableIRQ(EXTI15_10_IRQn);

    GNSS_SyncDateTime const* dt = gnss_datetime(&station);
    rtcIF.date.day = dt->date.day;
    rtcIF.date.month = dt->date.month;
    rtcIF.date.year = dt->date.year;
    rtcIF.time.sec = dt->time.second;
    rtcIF.time.min = dt->time.minute;
    rtcIF.time.hour = dt->time.hour;
    rtc_sync_datetime(&rtcIF);

    // Периодичный таймер для синхронизации времени с GNSS. Если не запущен - запустить
    if(xTimerIsTimerActive(tmrSyncTimeHandle) == pdFALSE) {
      static const TickType_t syncPeriod = (1 * 60 * 60 * 1000) / portTICK_PERIOD_MS;   // 1 час
      xTimerChangePeriod(tmrSyncTimeHandle, syncPeriod, portMAX_DELAY);
      xTimerStart(tmrSyncTimeHandle, portMAX_DELAY);
    }
  }
}

static FT_Core eve2;
static AppUI ui;
static void start_display(void* argument)
{
  {
    const FT_Display param = {
        .h.size = 800,
        .h.cycle = 928,
        .h.offset = 88,
        .h.sync0 = 0,
        .h.sync1 = 48,
        .v.size = 480,
        .v.cycle = 525,
        .v.offset = 32,
        .v.sync0 = 0,
        .v.sync1 = 3,
        .pclk = 2,
        .swizzle = 0,
        .pclkpol = 0,
        .cspread = 1,
        .dither = 1
    };
    ft_core_init(&eve2, &spiIF_TFT, &param, TFT_PD_GPIO_Port, TFT_PD_Pin, 20);

    const FT_Theme theme = {
        .clearColor.value = 0xFFFFFFFF,
        .color.value = 0xFF,
        .fgColor.value = 0xFF8000FF,
        .bgColor.value = 0xFF
    };
    ft_core_config(&eve2, 256, 16, &theme);
  }

  app_ui_manager_init(&ui, &eve2);
  while(bTrue) {
    const uint32_t start = xTaskGetTickCount();
    app_ui_manager(&ui);
    osDelayUntil(start+pdMS_TO_TICKS(20));
  }
}

static void system_config()
{
  xTaskCreate(start_service_interrupt, "serviceInt", 128, NULL, osPriorityAboveNormal, NULL);

  spi_init();
  xTaskCreate(start_service_spi, "serviceSPI", 128, NULL, osPriorityAboveNormal, NULL);

  i2c_init();
  xTaskCreate(start_service_i2c, "serviceI2C", 128, NULL, osPriorityAboveNormal, NULL);

  usbp_ctrl_config();

  mt25q_init(mt25q_instance());
  mt25q_config(mt25q_instance());

  xTaskCreate(start_service_sensors, "serviceSensor", 150, NULL, osPriorityNormal, NULL);
  xTaskCreate(start_service_sd, "serviceSD", 448, NULL, osPriorityNormal, NULL);

  flow_init();
  sta_init();
  flash_read_params(&station);
  xTaskCreate(start_gnss_rx1, "gnssRx1", 500, NULL, osPriorityNormal, NULL);
  xTaskCreate(start_gnss_tx1, "gnssTx1", 128, NULL, osPriorityNormal, NULL);
  xTaskCreate(start_ppm_rx0, "ppmRx1", 500, NULL, osPriorityNormal, NULL);
  xTaskCreate(start_ppm_tx0, "ppmTx1", 128, NULL, osPriorityNormal, NULL);
  xTaskCreate(start_ppm_init, "ppmInit", 380, NULL, osPriorityAboveNormal, NULL);
  xTaskCreate(start_cdc_rx, "cdcRx", 400, NULL, osPriorityNormal, NULL);
  xTaskCreate(start_cdc_tx, "cdcTx", 128, NULL, osPriorityNormal, NULL);
  xTaskCreate(start_mi_rx, "miRx", 400, NULL, osPriorityNormal, NULL);
  xTaskCreate(start_mi_tx, "miTx", 128, NULL, osPriorityNormal, NULL);
  xTaskCreate(start_jet_rx, "jetRx", 250, NULL, osPriorityNormal, NULL);
  xTaskCreate(start_jet_tx, "jetTx", 128, NULL, osPriorityNormal, NULL);
  xTaskCreate(start_bluetooth_tx, "blthTx", 128, NULL, osPriorityNormal, NULL);
  xTaskCreate(start_sta_regular, "staRegular", 544, NULL, osPriorityNormal, NULL);

  gnss_config(&station, &flowCtrl);
  xTaskCreate(start_sync_time, "timeSync", 128, NULL, osPriorityHigh, NULL);

  xTaskCreate(start_display, "display", 320, NULL, osPriorityNormal, NULL);

  bluetooth = blth_create(&huart1, BLTH_RESET_GPIO_Port, BLTH_RESET_Pin);
}
/* USER CODE END Application */
